# MK21D5WS register map
File version: 1.6
Registers are 32-bit, read-write, reset 0x0 unless marked. A register's access mark holds for its fields unless they carry their own. Offsets are from the block's base; [hi:lo] are bit positions; {n}, {i} and the like mark numbered series.

## LPTMR0 — Low Power Timer
Base 0x40040000; register names take the prefix LPTMR0_
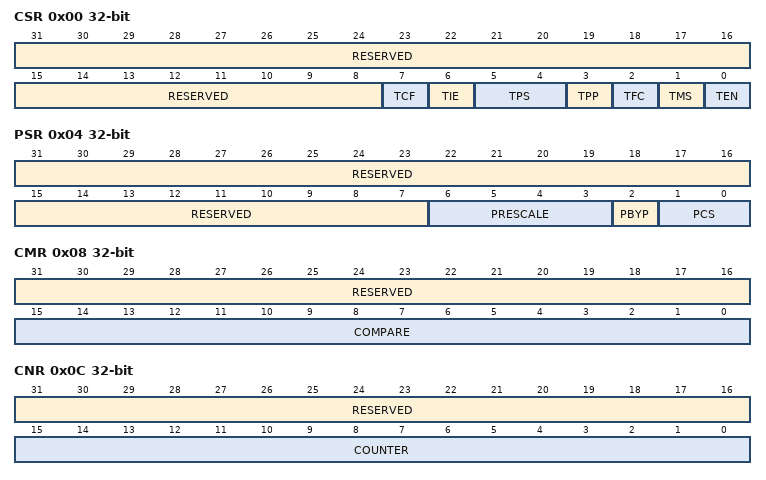
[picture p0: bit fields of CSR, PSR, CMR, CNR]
0x00 CSR — Low Power Timer Control Status Register
  [31:8] RESERVED ro
  [7] TCF — Timer Compare Flag
    0=The value of CNR is not equal to CMR and increments; 1=The value of CNR is equal to CMR and increments
  [6] TIE — Timer Interrupt Enable
    0=Timer interrupt disabled; 1=Timer interrupt enabled
  [5:4] TPS — Timer Pin Select
    {v}=Pulse counter input {v} is selected (v=0..3)
  [3] TPP — Timer Pin Polarity
    0=Pulse Counter input source is active-high, and the CNR will increment on the rising-edge; 1=Pulse Counter input source is active-low, and the CNR will increment on the falling-edge
  [2] TFC — Timer Free-Running Counter
    0=CNR is reset whenever TCF is set; 1=CNR is reset on overflow
  [1] TMS — Timer Mode Select
    0=Time Counter mode; 1=Pulse Counter mode
  [0] TEN — Timer Enable
    0=LPTMR is disabled and internal logic is reset; 1=LPTMR is enabled
0x04 PSR — Low Power Timer Prescale Register
  [31:7] RESERVED ro
  [6:3] PRESCALE — Prescale Value
    0=Prescaler divides the prescaler clock by 2; glitch filter does not support this configuration; 1=Prescaler divides the prescaler clock by 4; glitch filter recognizes change on input pin after 2 rising clock edges; 2=Prescaler divides the prescaler clock by 8; glitch filter recognizes change on input pin after 4 rising clock edges; 3=Prescaler divides the prescaler clock by 16; glitch filter recognizes change on input pin after 8 rising clock edges; 4=Prescaler divides the prescaler clock by 32; glitch filter recognizes change on input pin after 16 rising clock edges; 5=Prescaler divides the prescaler clock by 64; glitch filter recognizes change on input pin after 32 rising clock edges; 6=Prescaler divides the prescaler clock by 128; glitch filter recognizes change on input pin after 64 rising clock edges; 7=Prescaler divides the prescaler clock by 256; glitch filter recognizes change on input pin after 128 rising clock edges; 8=Prescaler divides the prescaler clock by 512; glitch filter recognizes change on input pin after 256 rising clock edges; 9=Prescaler divides the prescaler clock by 1024; glitch filter recognizes change on input pin after 512 rising clock edges; 10=Prescaler divides the prescaler clock by 2048; glitch filter recognizes change on input pin after 1024 rising clock edges; 11=Prescaler divides the prescaler clock by 4096; glitch filter recognizes change on input pin after 2048 rising clock edges; 12=Prescaler divides the prescaler clock by 8192; glitch filter recognizes change on input pin after 4096 rising clock edges; 13=Prescaler divides the prescaler clock by 16,384; glitch filter recognizes change on input pin after 8192 rising clock edges; 14=Prescaler divides the prescaler clock by 32,768; glitch filter recognizes change on input pin after 16,384 rising clock edges; 15=Prescaler divides the prescaler clock by 65,536; glitch filter recognizes change on input pin after 32,768 rising clock edges
  [2] PBYP — Prescaler Bypass
    0=Prescaler/glitch filter is enabled; 1=Prescaler/glitch filter is bypassed
  [1:0] PCS — Prescaler Clock Select
    {v}=Prescaler/glitch filter clock {v} selected (v=0..3)
0x08 CMR — Low Power Timer Compare Register
  [31:16] RESERVED ro
  [15:0] COMPARE — Compare Value
0x0C CNR ro — Low Power Timer Counter Register
  [31:16] RESERVED
  [15:0] COUNTER — Counter Value

## RFSYS — System register file
Base 0x40041000; register names take the prefix RFSYS_
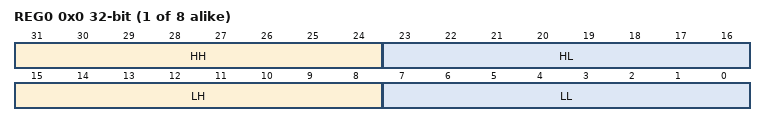
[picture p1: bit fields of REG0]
{0x0+4i} REG{i} (i=0..7) — Register file register
  [31:24] HH, [23:16] HL, [15:8] LH, [7:0] LL

## WDOG — Generation 2008 Watchdog Timer
Base 0x40052000; register names take the prefix WDOG_
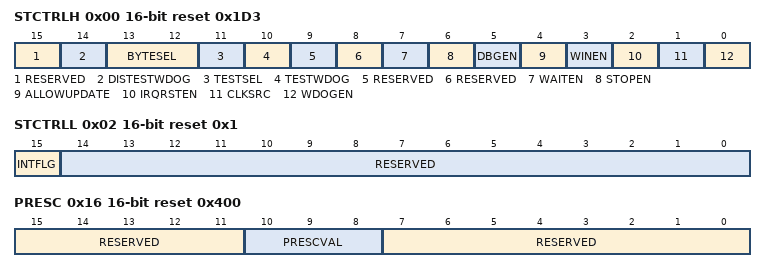
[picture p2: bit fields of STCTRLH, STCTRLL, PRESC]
0x00 STCTRLH 16-bit reset 0x1D3 — Watchdog Status and Control Register High
  [15] RESERVED ro
  [14] DISTESTWDOG
    0=WDOG functional test mode is not disabled; 1=WDOG functional test mode is disabled permanently until reset
  [13:12] BYTESEL
    {v}=Byte {v} selected (v=0..3)
  [11] TESTSEL
    0=Quick test. The timer runs in normal operation. You can load a small time-out value to do a quick test.; 1=Byte test. Puts the timer in the byte test mode where individual bytes of the timer are enabled for operation and are compared for time-out against the corresponding byte of the programmed time-out value. Select the byte through BYTESEL[1:0] for testing.
  [10] TESTWDOG
  [9] RESERVED ro
  [8] RESERVED
  [7] WAITEN
    0=WDOG is disabled in CPU Wait mode; 1=WDOG is enabled in CPU Wait mode
  [6] STOPEN
    0=WDOG is disabled in CPU Stop mode; 1=WDOG is enabled in CPU Stop mode
  [5] DBGEN
    0=WDOG is disabled in CPU Debug mode; 1=WDOG is enabled in CPU Debug mode
  [4] ALLOWUPDATE
    0=No further updates allowed to WDOG write-once registers; 1=WDOG write-once registers can be unlocked for updating
  [3] WINEN
    0=Windowing mode is disabled; 1=Windowing mode is enabled
  [2] IRQRSTEN
    0=WDOG time-out generates reset only; 1=WDOG time-out initially generates an interrupt. After WCT, it generates a reset.
  [1] CLKSRC
    0=WDOG clock sourced from LPO ; 1=WDOG clock sourced from alternate clock source
  [0] WDOGEN
    0=WDOG is disabled; 1=WDOG is enabled
0x02 STCTRLL 16-bit reset 0x1 — Watchdog Status and Control Register Low
  [15] INTFLG, [14:0] RESERVED
0x04 TOVALH 16-bit reset 0x4C — Watchdog Time-out Value Register High
  [15:0] TOVALHIGH
0x06 TOVALL 16-bit reset 0x4B4C — Watchdog Time-out Value Register Low
  [15:0] TOVALLOW
0x08 WINH 16-bit — Watchdog Window Register High
  [15:0] WINHIGH
0x0A WINL 16-bit reset 0x10 — Watchdog Window Register Low
  [15:0] WINLOW
0x0C REFRESH 16-bit reset 0xB480 — Watchdog Refresh register
  [15:0] WDOGREFRESH
0x0E UNLOCK 16-bit reset 0xD928 — Watchdog Unlock register
  [15:0] WDOGUNLOCK
0x10 TMROUTH 16-bit — Watchdog Timer Output Register High
  [15:0] TIMEROUTHIGH
0x12 TMROUTL 16-bit — Watchdog Timer Output Register Low
  [15:0] TIMEROUTLOW
0x14 RSTCNT 16-bit — Watchdog Reset Count register
0x16 PRESC 16-bit reset 0x400 — Watchdog Prescaler register
  [15:11] RESERVED ro, [10:8] PRESCVAL, [7:0] RESERVED ro
